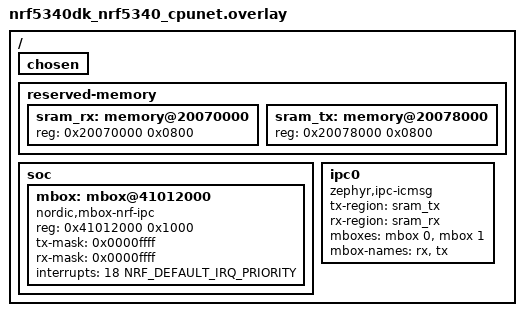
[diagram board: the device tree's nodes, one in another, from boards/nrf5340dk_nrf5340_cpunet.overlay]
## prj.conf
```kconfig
#
# Copyright (c) 2022 Nordic Semiconductor ASA
#
# SPDX-License-Identifier: LicenseRef-Nordic-5-Clause
#
# Enabling assert
CONFIG_ASSERT=y

# Logger configuration
CONFIG_LOG=y
CONFIG_LOG_DEFAULT_LEVEL=2
CONFIG_LOG_BACKEND_UART=y
CONFIG_LOG_STRDUP_BUF_COUNT=10

# Configuration required by Event Manager
CONFIG_EVENT_MANAGER=y
CONFIG_EVENT_MANAGER_PROXY=y
CONFIG_HEAP_MEM_POOL_SIZE=4096
CONFIG_REBOOT=y

CONFIG_PRINTK=y

CONFIG_IPC_SERVICE=y
#CONFIG_IPC_SERVICE_BACKEND_RPMSG=y
CONFIG_IPC_SERVICE_BACKEND_ICMSG=y
CONFIG_MBOX=y

#CONFIG_OPENAMP=y
#CONFIG_OPENAMP_MASTER=n

# Simplify debugging
CONFIG_RESET_ON_FATAL_ERROR=n

###################################
# Application configuration
###################################

CONFIG_APP_MODULE_CONTROLLER_ENABLE=y
CONFIG_APP_MODULE_SENSOR_SIMULATED_ENABLE=y
```

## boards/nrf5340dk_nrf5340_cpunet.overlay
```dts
/*
 * Copyright (c) 2021 Carlo Caione <ccaione@baylibre.com>
 *
 * SPDX-License-Identifier: Apache-2.0
 */

/ {
	chosen {
		/delete-property/ zephyr,ipc_shm;
	};

	reserved-memory {
		/delete-node/ memory@20070000;

		sram_rx: memory@20070000 {
			reg = <0x20070000 0x0800>;
		};

		sram_tx: memory@20078000 {
			reg = <0x20078000 0x0800>;
		};
	};

	soc {
		/delete-node/ ipc@41012000;

		mbox: mbox@41012000 {
			compatible = "nordic,mbox-nrf-ipc";
			reg = <0x41012000 0x1000>;
			tx-mask = <0x0000ffff>;
			rx-mask = <0x0000ffff>;
			interrupts = <18 NRF_DEFAULT_IRQ_PRIORITY>;
			#mbox-cells = <1>;
			status = "okay";
		};
	};

	ipc0: ipc0 {
		compatible = "zephyr,ipc-icmsg";
		tx-region = <&sram_tx>;
		rx-region = <&sram_rx>;
		mboxes = <&mbox 0>, <&mbox 1>;
		mbox-names = "rx", "tx";
		status = "okay";
	};
};
```

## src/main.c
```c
/*
 * Copyright (c) 2022 Nordic Semiconductor ASA
 *
 * SPDX-License-Identifier: LicenseRef-Nordic-5-Clause
 */

#include <zephyr.h>
#include <device.h>

#include <ipc/ipc_service.h>

#include <event_manager.h>
#include <event_manager_proxy.h>
#include <config_event.h>
#include <logging/log.h>

#define MODULE main_remote

LOG_MODULE_REGISTER(MODULE);

#define INIT_VALUE1 3

void main(void)
{
	int ret;
	const struct device *ipc_instance  = DEVICE_DT_GET(DT_NODELABEL(ipc0));

	printk("Event Manager Proxy remote_core started\n");

	ret = event_manager_init();
	if (ret) {
		LOG_ERR("Event Manager not initialized, err: %d", ret);
		__ASSERT_NO_MSG(false);
		return;
	}
	LOG_INF("Event manager initialized");

	ret = event_manager_proxy_add_remote(ipc_instance);
	if (ret) {
		LOG_ERR("Cannot add remote: %d", ret);
		__ASSERT_NO_MSG(false);
		return;
	}
	LOG_INF("Event proxy remote added");

	/* Listen to the events from the remote */
	ret = EVENT_MANAGER_PROXY_REGISTER_LISTENER(ipc_instance, config_event);
	if (ret) {
		LOG_ERR("Cannot register to remote config_event: %d", ret);
		__ASSERT_NO_MSG(false);
		return;
	}
	LOG_INF("Event proxy config_event registered");

	ret = event_manager_proxy_start();
	if (ret) {
		LOG_ERR("Cannot start event manager proxy: %d", ret);
		__ASSERT_NO_MSG(false);
		return;
	}

	/* We do not have to wait for remotes here as we do not send any event that
	 * would be fatal when missed.
	 */
	LOG_INF("Initialization finished successfully");
}
```
